# DA1469x register map
Vendor: Dialog; Series: DA1469x; File version: 1.2
CPU: CM33 r1p0, little endian, no MPU, FPU, 3 interrupt priority bits
Registers are 32-bit, read-write, reset 0x0 unless marked. A register's access mark holds for its fields unless they carry their own. Offsets are from the block's base; [hi:lo] are bit positions.

## SPI2 — SPI2 registers
Base 0x50020400
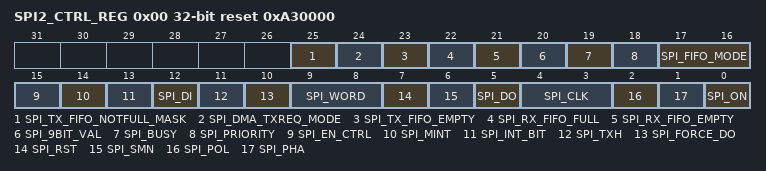
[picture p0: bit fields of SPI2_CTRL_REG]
0x00 SPI2_CTRL_REG reset 0xA30000 — SPI control register 0
  [25] SPI_TX_FIFO_NOTFULL_MASK — When 1, SPI Interrupt is generated when TX fifo is not full
  [24] SPI_DMA_TXREQ_MODE — In case SPI_FIFO_MODE=3 0 = DMA TX request is generated when transaction is finished 1 = DMA TX request is generated when tx buffer is free
  [23] SPI_TX_FIFO_EMPTY ro — 0 = Trasmit fifo is not empty 1 = Trasmit fifo is empty
  [22] SPI_RX_FIFO_FULL ro — 0 = Receive fifo is not full 1 = Receive fifo is full
  [21] SPI_RX_FIFO_EMPTY ro — 0 = Receive fifo is not empty 1 = Receive fifo is empty
  [20] SPI_9BIT_VAL — Determines the value of the first bit in 9 bits SPI mode.
  [19] SPI_BUSY ro — 0 = The SPI is not busy with a transfer. This means that either no TX-data is available or that the transfers have been suspended due to a full RX-FIFO. The SPI_CTRL_REG[SPI_INT_BIT] can be used to distinguish between these situations. 1 = The SPI is busy with a transfer.
  [18] SPI_PRIORITY — 0 = The SPI has low priority, the DMA request signals are reset after the corresponding acknowledge. 1 = The SPI has high priority, DMA request signals remain active until the FIFOS are filled/emptied, so the DMA holds the AHB bus.
  [17:16] SPI_FIFO_MODE — 0 = TX-FIFO and RX-FIFO used (Bidirectional mode). 1 = RX-FIFO used (Read Only Mode) TX-FIFO single depth, no flow control 2 = TX-FIFO used (Write Only Mode), RX-FIFO single depth, no flow control 3 = No FIFOs used (backwards compatible mode)
  [15] SPI_EN_CTRL — 0 = SPI_EN pin disabled in slave mode. Pin SPI_EN is don't care. 1 = SPI_EN pin enabled in slave mode.
  [14] SPI_MINT — 0 = Disable SPI_INT_BIT to ICU 1 = Enable SPI_INT_BIT to ICU.
  [13] SPI_INT_BIT ro — 0 = RX Register or FIFO is empty. 1 = SPI interrupt. Data has been transmitted and receivedMust be reset by SW by writing to SPI_CLEAR_INT_REG.
  [12] SPI_DI ro — Returns the actual value of pin SPI_DIN (delayed with two internal SPI clock cycles)
  [11] SPI_TXH ro — 0 = TX-FIFO is not full, data can be written. 1 = TX-FIFO is full, data can not be written.
  [10] SPI_FORCE_DO — 0 = normal operation 1 = Force SPIDO output level to value of SPI_DO.
  [9:8] SPI_WORD — 00 = 8 bits mode 01 = 16 bit mode 10 = 32 bits mode 11 = 9 bits mode. Only valid in master mode.
  [7] SPI_RST — 0 = normal operation 1 = Reset SPI. Same function as SPI_ON except that internal clock remain active.
  [6] SPI_SMN — Master/slave mode 0 = Master 1 = Slave
  [5] SPI_DO — Pin SPI_DO output level when SPI is idle or when SPI_FORCE_DO=1
  [4:3] SPI_CLK — Select SPI_CLK clock output frequency in master mode: 00 = SPI_CLK / 8 01 = SPI_CLK / 4 10 = SPI_CLK / 2 11 = SPI_CLK / 14
  [2] SPI_POL — Select SPI_CLK polarity. 0 = SPI_CLK is initially low. 1 = SPI_CLK is initially high.
  [1] SPI_PHA — Select SPI_CLK phase. See functional timing diagrams in SPI chapter
  [0] SPI_ON — 0 = SPI Module switched off (power saving). Everything is reset except SPI_CTRL_REG. When this bit is cleared the SPI will remain active in master mode until the shift register and holding register are both empty. 1 = SPI Module switched on. Should only be set after all control bits have their desired values. So two writes are needed!
0x04 SPI2_RX_TX_REG (reset mask 0x7FFFFFFF) — SPI RX/TX register0
  [31:0] SPI_DATA wo — Write: SPI_TX_REG output register 0 (TX-FIFO) Read: SPI_RX_REG input register 0 (RX-FIFO) In 8 or 9 bits mode bits 31 to 8 are not used, they contain old data. In 16 bits mode bits 31 to 16 are not used, they contain old data.
0x08 SPI2_CLEAR_INT_REG (reset mask 0x7FFFFFFF) — SPI clear interrupt register
  [31:0] SPI_CLEAR_INT wo — Writing any value to this register will clear the SPI_CTRL_REG[SPI_INT_BIT] Reading returns 0.
